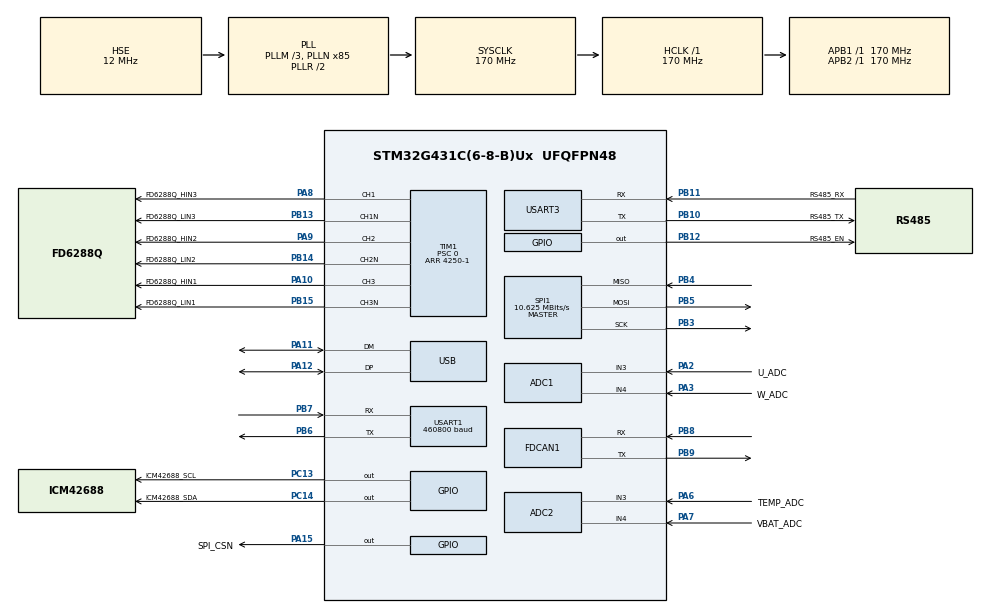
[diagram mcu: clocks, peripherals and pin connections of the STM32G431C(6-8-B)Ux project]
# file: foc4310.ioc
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ADC1.Channel-0\#ChannelRegularConversion=ADC_CHANNEL_VREFINT
ADC1.EnableInjectedConversion=ENABLE
ADC1.ExternalTrigConv=ADC_SOFTWARE_START
ADC1.ExternalTrigInjecConv=ADC_EXTERNALTRIGINJEC_T1_CC4
ADC1.ExternalTrigInjecConvEdge=ADC_EXTERNALTRIGINJECCONV_EDGE_FALLING
ADC1.InjNumberOfConversion=2
ADC1.InjectedChannel-2\#ChannelInjectedConversion=ADC_CHANNEL_3
ADC1.InjectedChannel-3\#ChannelInjectedConversion=ADC_CHANNEL_4
ADC1.InjectedOffsetNumber-2\#ChannelInjectedConversion=ADC_OFFSET_NONE
ADC1.InjectedOffsetNumber-3\#ChannelInjectedConversion=ADC_OFFSET_NONE
ADC1.InjectedRank-2\#ChannelInjectedConversion=1
ADC1.InjectedRank-3\#ChannelInjectedConversion=2
ADC1.InjectedSamplingTime-2\#ChannelInjectedConversion=ADC_SAMPLETIME_6CYCLES_5
ADC1.InjectedSamplingTime-3\#ChannelInjectedConversion=ADC_SAMPLETIME_6CYCLES_5
ADC1.NbrOfConversion=1
ADC1.NbrOfConversionFlag=1
ADC1.OffsetNumber-0\#ChannelRegularConversion=ADC_OFFSET_NONE
ADC1.Rank-0\#ChannelRegularConversion=1
ADC1.SamplingTime-0\#ChannelRegularConversion=ADC_SAMPLETIME_247CYCLES_5
ADC1.injectedQueueMode=DISABLE
ADC1.master=1
ADC2.Channel-2\#ChannelRegularConversion=ADC_CHANNEL_3
ADC2.Channel-3\#ChannelRegularConversion=ADC_CHANNEL_4
ADC2.ContinuousConvMode=ENABLE
ADC2.DMAContinuousRequests=ENABLE
ADC2.NbrOfConversion=2
ADC2.NbrOfConversionFlag=1
ADC2.OffsetNumber-2\#ChannelRegularConversion=ADC_OFFSET_NONE
ADC2.OffsetNumber-3\#ChannelRegularConversion=ADC_OFFSET_NONE
ADC2.Rank-2\#ChannelRegularConversion=1
ADC2.Rank-3\#ChannelRegularConversion=2
ADC2.SamplingTime-2\#ChannelRegularConversion=ADC_SAMPLETIME_12CYCLES_5
ADC2.SamplingTime-3\#ChannelRegularConversion=ADC_SAMPLETIME_12CYCLES_5
Dma.ADC2.2.Direction=DMA_PERIPH_TO_MEMORY
Dma.ADC2.2.EventEnable=DISABLE
Dma.ADC2.2.Instance=DMA1_Channel1
Dma.ADC2.2.MemDataAlignment=DMA_MDATAALIGN_HALFWORD
Dma.ADC2.2.MemInc=DMA_MINC_ENABLE
Dma.ADC2.2.Mode=DMA_CIRCULAR
Dma.ADC2.2.PeriphDataAlignment=DMA_PDATAALIGN_HALFWORD
Dma.ADC2.2.PeriphInc=DMA_PINC_DISABLE
Dma.ADC2.2.Polarity=HAL_DMAMUX_REQ_GEN_RISING
Dma.ADC2.2.Priority=DMA_PRIORITY_HIGH
Dma.ADC2.2.RequestNumber=1
Dma.ADC2.2.SignalID=NONE
Dma.ADC2.2.SyncEnable=DISABLE
Dma.ADC2.2.SyncPolarity=HAL_DMAMUX_SYNC_NO_EVENT
Dma.ADC2.2.SyncRequestNumber=1
Dma.ADC2.2.SyncSignalID=NONE
Dma.Request0=USART1_TX
Dma.Request1=USART1_RX
Dma.Request2=ADC2
Dma.USART1_RX.1.Direction=DMA_PERIPH_TO_MEMORY
Dma.USART1_RX.1.EventEnable=DISABLE
Dma.USART1_RX.1.Instance=DMA1_Channel3
Dma.USART1_RX.1.MemDataAlignment=DMA_MDATAALIGN_BYTE
Dma.USART1_RX.1.MemInc=DMA_MINC_ENABLE
Dma.USART1_RX.1.Mode=DMA_NORMAL
Dma.USART1_RX.1.PeriphDataAlignment=DMA_PDATAALIGN_BYTE
Dma.USART1_RX.1.PeriphInc=DMA_PINC_DISABLE
Dma.USART1_RX.1.Polarity=HAL_DMAMUX_REQ_GEN_RISING
Dma.USART1_RX.1.Priority=DMA_PRIORITY_HIGH
Dma.USART1_RX.1.RequestNumber=1
Dma.USART1_RX.1.SignalID=NONE
Dma.USART1_RX.1.SyncEnable=DISABLE
Dma.USART1_RX.1.SyncPolarity=HAL_DMAMUX_SYNC_NO_EVENT
Dma.USART1_RX.1.SyncRequestNumber=1
Dma.USART1_RX.1.SyncSignalID=NONE
Dma.USART1_TX.0.Direction=DMA_MEMORY_TO_PERIPH
Dma.USART1_TX.0.EventEnable=DISABLE
Dma.USART1_TX.0.Instance=DMA1_Channel4
Dma.USART1_TX.0.MemDataAlignment=DMA_MDATAALIGN_BYTE
Dma.USART1_TX.0.MemInc=DMA_MINC_ENABLE
Dma.USART1_TX.0.Mode=DMA_NORMAL
Dma.USART1_TX.0.PeriphDataAlignment=DMA_PDATAALIGN_BYTE
Dma.USART1_TX.0.PeriphInc=DMA_PINC_DISABLE
Dma.USART1_TX.0.Polarity=HAL_DMAMUX_REQ_GEN_RISING
Dma.USART1_TX.0.Priority=DMA_PRIORITY_HIGH
Dma.USART1_TX.0.RequestNumber=1
Dma.USART1_TX.0.SignalID=NONE
Dma.USART1_TX.0.SyncEnable=DISABLE
Dma.USART1_TX.0.SyncPolarity=HAL_DMAMUX_SYNC_NO_EVENT
Dma.USART1_TX.0.SyncRequestNumber=1
Dma.USART1_TX.0.SyncSignalID=NONE
FDCAN1.CalculateBaudRateNominal=1000000
FDCAN1.CalculateTimeBitNominal=1000
FDCAN1.CalculateTimeQuantumNominal=100.0
FDCAN1.DataPrescaler=16
FDCAN1.DataTimeSeg1=10
FDCAN1.DataTimeSeg2=9
FDCAN1.FrameFormat=FDCAN_FRAME_CLASSIC
FDCAN1.NominalPrescaler=17
FDCAN1.NominalTimeSeg1=5
FDCAN1.NominalTimeSeg2=4
FDCAN1.ProtocolException=DISABLE
FDCAN1.StdFiltersNbr=2
Mcu.Family=STM32G4
Mcu.Name=STM32G431C(6-8-B)Ux
Mcu.Package=UFQFPN48
NVIC.ADC1_2_IRQn=true\:0\:0\:false\:false\:true\:true\:true\:true
NVIC.DMA1_Channel3_IRQn=true\:0\:0\:false\:false\:true\:false\:true\:true
NVIC.DMA1_Channel4_IRQn=true\:0\:0\:false\:false\:true\:false\:true\:true
NVIC.FDCAN1_IT0_IRQn=true\:1\:0\:true\:false\:true\:true\:true\:true
NVIC.PriorityGroup=NVIC_PRIORITYGROUP_2
NVIC.TIM1_UP_TIM16_IRQn=true\:0\:1\:false\:false\:true\:true\:true\:true
NVIC.TIM6_DAC_IRQn=true\:2\:0\:true\:false\:true\:true\:true\:true
NVIC.USART1_IRQn=true\:1\:0\:true\:false\:true\:true\:true\:true
NVIC.USB_LP_IRQn=true\:1\:0\:true\:false\:true\:false\:true\:true
PA10.GPIO_Label=FD6288Q_HIN1
PA10.Signal=S_TIM1_CH3
PA11.Mode=Device
PA11.Signal=USB_DM
PA12.Mode=Device
PA12.Signal=USB_DP
PA13.GPIO_Label=SWDIO
PA13.Mode=Serial_Wire
PA13.Signal=SYS_JTMS-SWDIO
PA14.GPIO_Label=SWCLK
PA14.Mode=Serial_Wire
PA14.Signal=SYS_JTCK-SWCLK
PA15.GPIO_Label=SPI_CSN
PA15.Signal=GPIO_Output
PA2.GPIO_Label=U_ADC
PA2.Mode=IN3-Single-Ended
PA2.Signal=ADC1_IN3
PA3.GPIO_Label=W_ADC
PA3.Mode=IN4-Single-Ended
PA3.Signal=ADC1_IN4
PA6.GPIO_Label=TEMP_ADC
PA6.Mode=IN3-Single-Ended
PA6.Signal=ADC2_IN3
PA7.GPIO_Label=VBAT_ADC
PA7.Mode=IN4-Single-Ended
PA7.Signal=ADC2_IN4
PA8.GPIO_Label=FD6288Q_HIN3
PA8.Signal=S_TIM1_CH1
PA9.GPIO_Label=FD6288Q_HIN2
PA9.Signal=S_TIM1_CH2
PB10.GPIO_Label=RS485_TX
PB10.Mode=Asynchronous
PB10.Signal=USART3_TX
PB11.GPIO_Label=RS485_RX
PB11.Mode=Asynchronous
PB11.Signal=USART3_RX
PB12.GPIO_Label=RS485_EN
PB12.Signal=GPIO_Output
PB13.GPIO_Label=FD6288Q_LIN3
PB13.Mode=PWM Generation1 CH1 CH1N
PB13.Signal=TIM1_CH1N
PB14.GPIO_Label=FD6288Q_LIN2
PB14.Mode=PWM Generation2 CH2 CH2N
PB14.Signal=TIM1_CH2N
PB15.GPIO_Label=FD6288Q_LIN1
PB15.Mode=PWM Generation3 CH3 CH3N
PB15.Signal=TIM1_CH3N
PB3.Mode=Full_Duplex_Master
PB3.Signal=SPI1_SCK
PB4.Mode=Full_Duplex_Master
PB4.Signal=SPI1_MISO
PB5.Mode=Full_Duplex_Master
PB5.Signal=SPI1_MOSI
PB6.GPIO_PuPd=GPIO_NOPULL
PB6.GPIO_Speed=GPIO_SPEED_FREQ_LOW
PB6.Mode=Asynchronous
PB6.Signal=USART1_TX
PB7.GPIO_PuPd=GPIO_NOPULL
PB7.GPIO_Speed=GPIO_SPEED_FREQ_LOW
PB7.Mode=Asynchronous
PB7.Signal=USART1_RX
PB8-BOOT0.Mode=FDCAN_Activate
PB8-BOOT0.Signal=FDCAN1_RX
PB9.Mode=FDCAN_Activate
PB9.Signal=FDCAN1_TX
PC13.GPIO_Label=ICM42688_SCL
PC13.Signal=GPIO_Output
PC14-OSC32_IN.GPIO_Label=ICM42688_SDA
PC14-OSC32_IN.Signal=GPIO_Output
PF0-OSC_IN.Mode=HSE-External-Oscillator
PF0-OSC_IN.Signal=RCC_OSC_IN
PF1-OSC_OUT.Mode=HSE-External-Oscillator
PF1-OSC_OUT.Signal=RCC_OSC_OUT
ProjectManager.HeapSize=0x1500
ProjectManager.StackSize=0x1500
ProjectManager.TargetToolchain=CMake
RCC.ADC12Freq_Value=170000000
RCC.AHBFreq_Value=170000000
RCC.APB1Freq_Value=170000000
RCC.APB1TimFreq_Value=170000000
RCC.APB2Freq_Value=170000000
RCC.APB2TimFreq_Value=170000000
RCC.CK48CLockSelection=RCC_USBCLKSOURCE_HSI48
RCC.CortexFreq_Value=170000000
RCC.EXTERNAL_CLOCK_VALUE=12288000
RCC.HCLKFreq_Value=170000000
RCC.HSE_VALUE=12000000
RCC.HSI48_VALUE=48000000
RCC.HSI_VALUE=16000000
RCC.LSE_VALUE=32768
RCC.PLLM=RCC_PLLM_DIV3
RCC.PLLN=85
RCC.PLLSourceVirtual=RCC_PLLSOURCE_HSE
RCC.SYSCLKFreq_VALUE=170000000
RCC.SYSCLKSource=RCC_SYSCLKSOURCE_PLLCLK
RCC.USBFreq_Value=48000000
RCC.VCOOutputFreq_Value=340000000
SH.S_TIM1_CH1.0=TIM1_CH1,PWM Generation1 CH1 CH1N
SH.S_TIM1_CH2.0=TIM1_CH2,PWM Generation2 CH2 CH2N
SH.S_TIM1_CH3.0=TIM1_CH3,PWM Generation3 CH3 CH3N
SPI1.BaudRatePrescaler=SPI_BAUDRATEPRESCALER_16
SPI1.CLKPhase=SPI_PHASE_2EDGE
SPI1.CalculateBaudRate=10.625 MBits/s
SPI1.DataSize=SPI_DATASIZE_16BIT
SPI1.Direction=SPI_DIRECTION_2LINES
SPI1.Mode=SPI_MODE_MASTER
SPI1.VirtualType=VM_MASTER
STMicroelectronics.X-CUBE-ALGOBUILD.1.4.0.LibraryCcDSPOoLibraryJjDSPOoLibrary=true
TIM1.AutoReloadPreload=TIM_AUTORELOAD_PRELOAD_ENABLE
TIM1.Channel-PWM\ Generation1\ CH1\ CH1N=TIM_CHANNEL_1
TIM1.Channel-PWM\ Generation2\ CH2\ CH2N=TIM_CHANNEL_2
TIM1.Channel-PWM\ Generation3\ CH3\ CH3N=TIM_CHANNEL_3
TIM1.Channel-PWM\ Generation4\ No\ Output=TIM_CHANNEL_4
TIM1.CounterMode=TIM_COUNTERMODE_CENTERALIGNED1
TIM1.DeadTime=50
TIM1.OCMode_PWM-PWM\ Generation1\ CH1\ CH1N=TIM_OCMODE_PWM1
TIM1.OCMode_PWM-PWM\ Generation2\ CH2\ CH2N=TIM_OCMODE_PWM1
TIM1.OCMode_PWM-PWM\ Generation3\ CH3\ CH3N=TIM_OCMODE_PWM1
TIM1.OCMode_PWM-PWM\ Generation4\ No\ Output=TIM_OCMODE_PWM1
TIM1.PeriodNoDither=4250-1
TIM1.Prescaler=0
TIM1.PulseNoDither_4=4250 - 10 - 1
TIM1.RepetitionCounter=0
TIM1.TIM_MasterOutputTrigger=TIM_TRGO_RESET
TIM1.TIM_MasterSlaveMode=TIM_MASTERSLAVEMODE_DISABLE
TIM6.AutoReloadPreload=TIM_AUTORELOAD_PRELOAD_ENABLE
TIM6.PeriodNoDither=1000 - 1
TIM6.Prescaler=170 - 1
USART1.AutoBaudRateEnableParam=UART_ADVFEATURE_AUTOBAUDRATE_DISABLE
USART1.BaudRate=460800
USART1.FIFOMode=FIFOMODE_ENABLE
USART1.VirtualMode-Asynchronous=VM_ASYNC
USART3.VirtualMode-Asynchronous=VM_ASYNC
USB_DEVICE.CLASS_NAME_FS=CDC
USB_DEVICE.VirtualMode=Cdc
USB_DEVICE.VirtualModeFS=Cdc_FS
VP_ADC1_Vref_Input.Mode=IN-Vrefint
VP_STMicroelectronics.X-CUBE-ALGOBUILD_VS_DSPOoLibraryJjLibrary_1.4.0_1.4.0.Mode=DSPOoLibraryJjLibrary
VP_SYS_VS_DBSignals.Mode=DisableDeadBatterySignals
VP_TIM1_VS_ClockSourceINT.Mode=Internal
VP_TIM1_VS_no_output4.Mode=PWM Generation4 No Output
VP_TIM6_VS_ClockSourceINT.Mode=Enable_Timer
VP_USB_DEVICE_VS_USB_DEVICE_CDC_FS.Mode=CDC_FS
board=custom

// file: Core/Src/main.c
/* USER CODE BEGIN Header */
/**
  ******************************************************************************
  * @file           : main.c
  * @brief          : Main program body
  ******************************************************************************
  * @attention
  *
  * Copyright (c) 2026 STMicroelectronics.
  * All rights reserved.
  *
  * This software is licensed under terms that can be found in the LICENSE file
  * in the root directory of this software component.
  * If no LICENSE file comes with this software, it is provided AS-IS.
  *
  ******************************************************************************
  */
/* USER CODE END Header */
#include "main.h"
#include "adc.h"
#include "dma.h"
#include "fdcan.h"
#include "spi.h"
#include "tim.h"
#include "usart.h"
#include "usb_device.h"
#include "gpio.h"

/* USER CODE BEGIN Includes */
#include "usr_code.h"
/* USER CODE END Includes */

void SystemClock_Config(void);

int main(void)
{

  /* MCU Configuration--------------------------------------------------------*/

  /* Reset of all peripherals, Initializes the Flash interface and the Systick. */
  HAL_Init();

  /* Configure the system clock */
  SystemClock_Config();

  /* Initialize all configured peripherals */
  MX_GPIO_Init();
  MX_DMA_Init();
  MX_ADC1_Init();
  MX_FDCAN1_Init();
  MX_SPI1_Init();
  MX_TIM1_Init();
  MX_USART1_UART_Init();
  MX_USART3_UART_Init();
  MX_USB_Device_Init();
  MX_ADC2_Init();
  MX_TIM6_Init();
  /* USER CODE BEGIN 2 */
  setup();
  /* USER CODE END 2 */

  /* Infinite loop */
  /* USER CODE BEGIN WHILE */
  while (1)
  {
    loop();
    /* USER CODE END WHILE */

  }
}

void SystemClock_Config(void)
{
  RCC_OscInitTypeDef RCC_OscInitStruct = {0};
  RCC_ClkInitTypeDef RCC_ClkInitStruct = {0};

  /** Configure the main internal regulator output voltage
  */
  HAL_PWREx_ControlVoltageScaling(PWR_REGULATOR_VOLTAGE_SCALE1_BOOST);

  /** Initializes the RCC Oscillators according to the specified parameters
  * in the RCC_OscInitTypeDef structure.
  */
  RCC_OscInitStruct.OscillatorType = RCC_OSCILLATORTYPE_HSI48|RCC_OSCILLATORTYPE_HSE;
  RCC_OscInitStruct.HSEState = RCC_HSE_ON;
  RCC_OscInitStruct.HSI48State = RCC_HSI48_ON;
  RCC_OscInitStruct.PLL.PLLState = RCC_PLL_ON;
  RCC_OscInitStruct.PLL.PLLSource = RCC_PLLSOURCE_HSE;
  RCC_OscInitStruct.PLL.PLLM = RCC_PLLM_DIV3;
  RCC_OscInitStruct.PLL.PLLN = 85;
  RCC_OscInitStruct.PLL.PLLP = RCC_PLLP_DIV2;
  RCC_OscInitStruct.PLL.PLLQ = RCC_PLLQ_DIV2;
  RCC_OscInitStruct.PLL.PLLR = RCC_PLLR_DIV2;
  if (HAL_RCC_OscConfig(&RCC_OscInitStruct) != HAL_OK)
  {
    Error_Handler();
  }

  /** Initializes the CPU, AHB and APB buses clocks
  */
  RCC_ClkInitStruct.ClockType = RCC_CLOCKTYPE_HCLK|RCC_CLOCKTYPE_SYSCLK
                              |RCC_CLOCKTYPE_PCLK1|RCC_CLOCKTYPE_PCLK2;
  RCC_ClkInitStruct.SYSCLKSource = RCC_SYSCLKSOURCE_PLLCLK;
  RCC_ClkInitStruct.AHBCLKDivider = RCC_SYSCLK_DIV1;
  RCC_ClkInitStruct.APB1CLKDivider = RCC_HCLK_DIV1;
  RCC_ClkInitStruct.APB2CLKDivider = RCC_HCLK_DIV1;

  if (HAL_RCC_ClockConfig(&RCC_ClkInitStruct, FLASH_LATENCY_4) != HAL_OK)
  {
    Error_Handler();
  }
}

void Error_Handler(void)
{
  __disable_irq();
  while (1)
  {
  }
}
